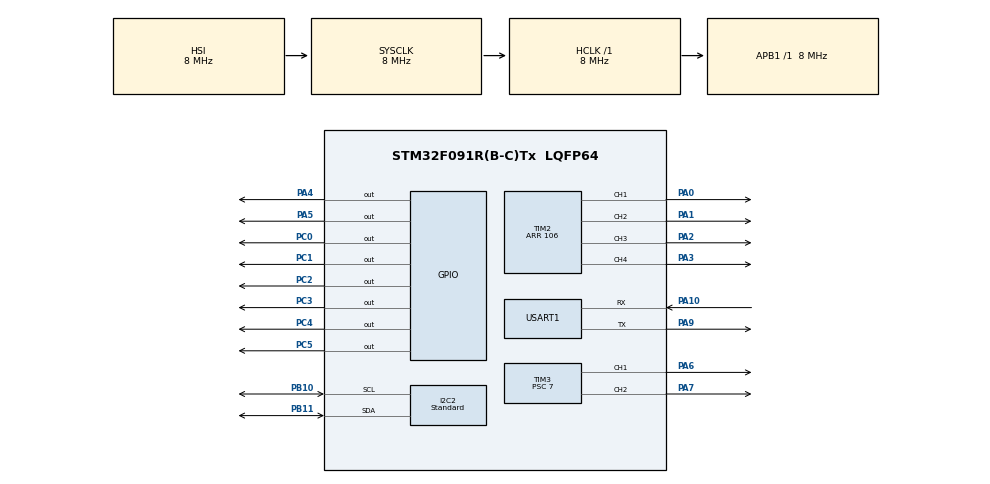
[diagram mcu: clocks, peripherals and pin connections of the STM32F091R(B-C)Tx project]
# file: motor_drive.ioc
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Dma.I2C2_RX.0.Direction=DMA_PERIPH_TO_MEMORY
Dma.I2C2_RX.0.Instance=DMA1_Channel5
Dma.I2C2_RX.0.MemDataAlignment=DMA_MDATAALIGN_BYTE
Dma.I2C2_RX.0.MemInc=DMA_MINC_ENABLE
Dma.I2C2_RX.0.Mode=DMA_NORMAL
Dma.I2C2_RX.0.PeriphDataAlignment=DMA_PDATAALIGN_BYTE
Dma.I2C2_RX.0.PeriphInc=DMA_PINC_DISABLE
Dma.I2C2_RX.0.Priority=DMA_PRIORITY_HIGH
Dma.I2C2_TX.1.Direction=DMA_MEMORY_TO_PERIPH
Dma.I2C2_TX.1.Instance=DMA1_Channel4
Dma.I2C2_TX.1.MemDataAlignment=DMA_MDATAALIGN_BYTE
Dma.I2C2_TX.1.MemInc=DMA_MINC_ENABLE
Dma.I2C2_TX.1.Mode=DMA_NORMAL
Dma.I2C2_TX.1.PeriphDataAlignment=DMA_PDATAALIGN_BYTE
Dma.I2C2_TX.1.PeriphInc=DMA_PINC_DISABLE
Dma.I2C2_TX.1.Priority=DMA_PRIORITY_HIGH
Dma.Request0=I2C2_RX
Dma.Request1=I2C2_TX
Dma.Request2=USART1_RX
Dma.Request3=USART1_TX
Dma.USART1_RX.2.Direction=DMA_PERIPH_TO_MEMORY
Dma.USART1_RX.2.Instance=DMA1_Channel1
Dma.USART1_RX.2.MemDataAlignment=DMA_MDATAALIGN_BYTE
Dma.USART1_RX.2.MemInc=DMA_MINC_ENABLE
Dma.USART1_RX.2.Mode=DMA_CIRCULAR
Dma.USART1_RX.2.PeriphDataAlignment=DMA_PDATAALIGN_BYTE
Dma.USART1_RX.2.PeriphInc=DMA_PINC_DISABLE
Dma.USART1_RX.2.Priority=DMA_PRIORITY_LOW
Dma.USART1_TX.3.Direction=DMA_MEMORY_TO_PERIPH
Dma.USART1_TX.3.Instance=DMA1_Channel2
Dma.USART1_TX.3.MemDataAlignment=DMA_MDATAALIGN_BYTE
Dma.USART1_TX.3.MemInc=DMA_MINC_ENABLE
Dma.USART1_TX.3.Mode=DMA_NORMAL
Dma.USART1_TX.3.PeriphDataAlignment=DMA_PDATAALIGN_BYTE
Dma.USART1_TX.3.PeriphInc=DMA_PINC_DISABLE
Dma.USART1_TX.3.Priority=DMA_PRIORITY_LOW
I2C2.I2C_Speed_Mode=I2C_Standard
I2C2.Speed=88
I2C2.Timing=0x00101D37
Mcu.Family=STM32F0
Mcu.Name=STM32F091R(B-C)Tx
Mcu.Package=LQFP64
NVIC.DMA1_Ch1_IRQn=true\:0\:0\:false\:false\:true\:false\:true\:true
NVIC.DMA1_Ch2_3_DMA2_Ch1_2_IRQn=true\:0\:0\:false\:false\:true\:false\:true\:true
NVIC.DMA1_Ch4_7_DMA2_Ch3_5_IRQn=true\:0\:0\:false\:false\:true\:false\:true\:true
NVIC.I2C2_IRQn=true\:0\:0\:false\:false\:true\:true\:true\:true
NVIC.TIM6_DAC_IRQn=true\:0\:0\:false\:false\:true\:true\:true\:true
NVIC.USART1_IRQn=true\:0\:0\:false\:false\:true\:true\:true\:true
PA0.Signal=S_TIM2_CH1_ETR
PA1.Signal=S_TIM2_CH2
PA10.Mode=Asynchronous
PA10.Signal=USART1_RX
PA2.Signal=S_TIM2_CH3
PA3.Signal=S_TIM2_CH4
PA4.Signal=GPIO_Output
PA5.Signal=GPIO_Output
PA6.Signal=S_TIM3_CH1
PA7.Signal=S_TIM3_CH2
PA9.Mode=Asynchronous
PA9.Signal=USART1_TX
PB10.Mode=I2C
PB10.Signal=I2C2_SCL
PB11.Mode=I2C
PB11.Signal=I2C2_SDA
PC0.Signal=GPIO_Output
PC1.Signal=GPIO_Output
PC2.Signal=GPIO_Output
PC3.Signal=GPIO_Output
PC4.Signal=GPIO_Output
PC5.Signal=GPIO_Output
PF0-OSC_IN.Mode=HSE-External-Oscillator
PF0-OSC_IN.Signal=RCC_OSC_IN
PF1-OSC_OUT.Mode=HSE-External-Oscillator
PF1-OSC_OUT.Signal=RCC_OSC_OUT
ProjectManager.HeapSize=0x200
ProjectManager.StackSize=0x400
ProjectManager.TargetToolchain=STM32CubeIDE
RCC.AHBFreq_Value=8000000
RCC.APB1Freq_Value=8000000
RCC.APB1TimFreq_Value=8000000
RCC.HCLKFreq_Value=8000000
RCC.SYSCLKFreq_VALUE=8000000
SH.S_TIM2_CH1_ETR.0=TIM2_CH1,PWM Generation1 CH1
SH.S_TIM2_CH2.0=TIM2_CH2,PWM Generation2 CH2
SH.S_TIM2_CH3.0=TIM2_CH3,PWM Generation3 CH3
SH.S_TIM2_CH4.0=TIM2_CH4,PWM Generation4 CH4
SH.S_TIM3_CH1.0=TIM3_CH1,PWM Generation1 CH1
SH.S_TIM3_CH2.0=TIM3_CH2,PWM Generation2 CH2
TIM2.Channel-PWM\ Generation1\ CH1=TIM_CHANNEL_1
TIM2.Channel-PWM\ Generation2\ CH2=TIM_CHANNEL_2
TIM2.Channel-PWM\ Generation3\ CH3=TIM_CHANNEL_3
TIM2.Channel-PWM\ Generation4\ CH4=TIM_CHANNEL_4
TIM2.Period=106
TIM2.Pulse-PWM\ Generation2\ CH2=0
TIM3.Channel-PWM\ Generation1\ CH1=TIM_CHANNEL_1
TIM3.Channel-PWM\ Generation2\ CH2=TIM_CHANNEL_2
TIM3.Period=19999
TIM3.Prescaler=7
TIM6.AutoReloadPreload=TIM_AUTORELOAD_PRELOAD_ENABLE
TIM6.Period=1947
TIM6.Prescaler=7
USART1.VirtualMode-Asynchronous=VM_ASYNC
VP_TIM2_VS_ClockSourceINT.Mode=Internal
VP_TIM3_VS_ClockSourceINT.Mode=Internal
VP_TIM6_VS_ClockSourceINT.Mode=Enable_Timer
board=custom

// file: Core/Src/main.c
/* USER CODE BEGIN Header */
/**
  ******************************************************************************
  * @file           : main.c
  * @brief          : Main program body
  ******************************************************************************
  * @attention
  *
  * Copyright (c) 2023 STMicroelectronics.
  * All rights reserved.
  *
  * This software is licensed under terms that can be found in the LICENSE file
  * in the root directory of this software component.
  * If no LICENSE file comes with this software, it is provided AS-IS.
  *
  ******************************************************************************
  */
/* USER CODE END Header */
#include "main.h"
#include "UART_Driver.h"
#include "i2c_proc.h"
#include "motor_proc.h"
#include "Jetson_Bridge.h"
#include "UART_Driver_Defines.h"
#include "servo_proc.h"

/* USER CODE BEGIN PD */
#define CW 1
#define CCW 0
/* USER CODE END PD */

I2C_HandleTypeDef hi2c2;
DMA_HandleTypeDef hdma_i2c2_rx;
DMA_HandleTypeDef hdma_i2c2_tx;
TIM_HandleTypeDef htim2;
TIM_HandleTypeDef htim3;
TIM_HandleTypeDef htim6;

UART_HandleTypeDef huart1;
DMA_HandleTypeDef hdma_usart1_rx;
DMA_HandleTypeDef hdma_usart1_tx;

void SystemClock_Config(void);
static void MX_GPIO_Init(void);
static void MX_DMA_Init(void);
static void MX_TIM2_Init(void);
static void MX_TIM3_Init(void);
static void MX_TIM6_Init(void);
static void MX_I2C2_Init(void);
static void MX_USART1_UART_Init(void);

int main(void)
{
  /* Reset of all peripherals, Initializes the Flash interface and the Systick. */
  HAL_Init();

  /* Configure the system clock */
  SystemClock_Config();

  /* Initialize all configured peripherals */
  MX_GPIO_Init();
  MX_DMA_Init();
  MX_TIM2_Init();
  MX_TIM3_Init();
  MX_TIM6_Init();
  MX_I2C2_Init();
  MX_USART1_UART_Init();

  HAL_TIM_PWM_Start(&htim2, TIM_CHANNEL_1);
  HAL_TIM_PWM_Start(&htim2, TIM_CHANNEL_2);
  HAL_TIM_PWM_Start(&htim2, TIM_CHANNEL_3);
  HAL_TIM_PWM_Start(&htim2, TIM_CHANNEL_4);
  HAL_TIM_PWM_Start(&htim3, TIM_CHANNEL_1);
  HAL_TIM_PWM_Start(&htim3, TIM_CHANNEL_2);

  MX_TIM6_Init();
  UART_Driver_RxInit();

  uint8_t gyro_on = 0b10000000;
  uint8_t accel_on = 0b10000000;
  (void) HAL_I2C_IsDeviceReady(&hi2c2, 212, 1, 100);
  (void) HAL_I2C_Mem_Write(&hi2c2, 212, 0x11, I2C_MEMADD_SIZE_8BIT, &gyro_on, 1, HAL_MAX_DELAY);
  (void) HAL_I2C_Mem_Write(&hi2c2, 212, 0x10, I2C_MEMADD_SIZE_8BIT, &accel_on, 1, HAL_MAX_DELAY);
  HAL_TIM_Base_Start_IT(&htim6);

  /* Infinite loop */
  while (1){
    if(!servo_proc_GetClose()) //open
    {
      servo1_control(120);
      servo2_control(20);
    }
    else //closed
    {
      servo2_control(120);
      for(int i=0;i<1000;i++)for(int j=0;j<150;j++)__NOP();
      servo1_control(160);
    }
  }
}

void SystemClock_Config(void)
{
  RCC_OscInitTypeDef RCC_OscInitStruct = {0};
  RCC_ClkInitTypeDef RCC_ClkInitStruct = {0};
  RCC_PeriphCLKInitTypeDef PeriphClkInit = {0};

  /** Initializes the RCC Oscillators according to the specified parameters
  * in the RCC_OscInitTypeDef structure.
  */
  RCC_OscInitStruct.OscillatorType = RCC_OSCILLATORTYPE_HSI;
  RCC_OscInitStruct.HSIState = RCC_HSI_ON;
  RCC_OscInitStruct.HSICalibrationValue = RCC_HSICALIBRATION_DEFAULT;
  RCC_OscInitStruct.PLL.PLLState = RCC_PLL_NONE;
  if (HAL_RCC_OscConfig(&RCC_OscInitStruct) != HAL_OK)
  {
    Error_Handler();
  }

  /** Initializes the CPU, AHB and APB buses clocks
  */
  RCC_ClkInitStruct.ClockType = RCC_CLOCKTYPE_HCLK|RCC_CLOCKTYPE_SYSCLK
                              |RCC_CLOCKTYPE_PCLK1;
  RCC_ClkInitStruct.SYSCLKSource = RCC_SYSCLKSOURCE_HSI;
  RCC_ClkInitStruct.AHBCLKDivider = RCC_SYSCLK_DIV1;
  RCC_ClkInitStruct.APB1CLKDivider = RCC_HCLK_DIV1;

  if (HAL_RCC_ClockConfig(&RCC_ClkInitStruct, FLASH_LATENCY_0) != HAL_OK)
  {
    Error_Handler();
  }
  PeriphClkInit.PeriphClockSelection = RCC_PERIPHCLK_USART1;
  PeriphClkInit.Usart1ClockSelection = RCC_USART1CLKSOURCE_PCLK1;
  if (HAL_RCCEx_PeriphCLKConfig(&PeriphClkInit) != HAL_OK)
  {
    Error_Handler();
  }
}

static void MX_I2C2_Init(void)
{
  hi2c2.Instance = I2C2;
  hi2c2.Init.Timing = 0x00101D37;
  hi2c2.Init.OwnAddress1 = 0;
  hi2c2.Init.AddressingMode = I2C_ADDRESSINGMODE_7BIT;
  hi2c2.Init.DualAddressMode = I2C_DUALADDRESS_DISABLE;
  hi2c2.Init.OwnAddress2 = 0;
  hi2c2.Init.OwnAddress2Masks = I2C_OA2_NOMASK;
  hi2c2.Init.GeneralCallMode = I2C_GENERALCALL_DISABLE;
  hi2c2.Init.NoStretchMode = I2C_NOSTRETCH_DISABLE;
  if (HAL_I2C_Init(&hi2c2) != HAL_OK)
  {
    Error_Handler();
  }

  /** Configure Analogue filter
  */
  if (HAL_I2CEx_ConfigAnalogFilter(&hi2c2, I2C_ANALOGFILTER_ENABLE) != HAL_OK)
  {
    Error_Handler();
  }

  /** Configure Digital filter
  */
  if (HAL_I2CEx_ConfigDigitalFilter(&hi2c2, 0) != HAL_OK)
  {
    Error_Handler();
  }
}

static void MX_TIM2_Init(void)
{
  TIM_ClockConfigTypeDef sClockSourceConfig = {0};
  TIM_MasterConfigTypeDef sMasterConfig = {0};
  TIM_OC_InitTypeDef sConfigOC = {0};

  htim2.Instance = TIM2;
  htim2.Init.Prescaler = 0;
  htim2.Init.CounterMode = TIM_COUNTERMODE_UP;
  htim2.Init.Period = 106;
  htim2.Init.ClockDivision = TIM_CLOCKDIVISION_DIV1;
  htim2.Init.AutoReloadPreload = TIM_AUTORELOAD_PRELOAD_DISABLE;
  if (HAL_TIM_Base_Init(&htim2) != HAL_OK)
  {
    Error_Handler();
  }
  sClockSourceConfig.ClockSource = TIM_CLOCKSOURCE_INTERNAL;
  if (HAL_TIM_ConfigClockSource(&htim2, &sClockSourceConfig) != HAL_OK)
  {
    Error_Handler();
  }
  if (HAL_TIM_PWM_Init(&htim2) != HAL_OK)
  {
    Error_Handler();
  }
  sMasterConfig.MasterOutputTrigger = TIM_TRGO_RESET;
  sMasterConfig.MasterSlaveMode = TIM_MASTERSLAVEMODE_DISABLE;
  if (HAL_TIMEx_MasterConfigSynchronization(&htim2, &sMasterConfig) != HAL_OK)
  {
    Error_Handler();
  }
  sConfigOC.OCMode = TIM_OCMODE_PWM1;
  sConfigOC.Pulse = 0;
  sConfigOC.OCPolarity = TIM_OCPOLARITY_HIGH;
  sConfigOC.OCFastMode = TIM_OCFAST_DISABLE;
  if (HAL_TIM_PWM_ConfigChannel(&htim2, &sConfigOC, TIM_CHANNEL_1) != HAL_OK)
  {
    Error_Handler();
  }
  if (HAL_TIM_PWM_ConfigChannel(&htim2, &sConfigOC, TIM_CHANNEL_2) != HAL_OK)
  {
    Error_Handler();
  }
  if (HAL_TIM_PWM_ConfigChannel(&htim2, &sConfigOC, TIM_CHANNEL_3) != HAL_OK)
  {
    Error_Handler();
  }
  if (HAL_TIM_PWM_ConfigChannel(&htim2, &sConfigOC, TIM_CHANNEL_4) != HAL_OK)
  {
    Error_Handler();
  }

  HAL_TIM_MspPostInit(&htim2);

}

static void MX_TIM3_Init(void)
{
  TIM_ClockConfigTypeDef sClockSourceConfig = {0};
  TIM_MasterConfigTypeDef sMasterConfig = {0};
  TIM_OC_InitTypeDef sConfigOC = {0};

  htim3.Instance = TIM3;
  htim3.Init.Prescaler = 7;
  htim3.Init.CounterMode = TIM_COUNTERMODE_UP;
  htim3.Init.Period = 19999;
  htim3.Init.ClockDivision = TIM_CLOCKDIVISION_DIV1;
  htim3.Init.AutoReloadPreload = TIM_AUTORELOAD_PRELOAD_DISABLE;
  if (HAL_TIM_Base_Init(&htim3) != HAL_OK)
  {
    Error_Handler();
  }
  sClockSourceConfig.ClockSource = TIM_CLOCKSOURCE_INTERNAL;
  if (HAL_TIM_ConfigClockSource(&htim3, &sClockSourceConfig) != HAL_OK)
  {
    Error_Handler();
  }
  if (HAL_TIM_PWM_Init(&htim3) != HAL_OK)
  {
    Error_Handler();
  }
  sMasterConfig.MasterOutputTrigger = TIM_TRGO_RESET;
  sMasterConfig.MasterSlaveMode = TIM_MASTERSLAVEMODE_DISABLE;
  if (HAL_TIMEx_MasterConfigSynchronization(&htim3, &sMasterConfig) != HAL_OK)
  {
    Error_Handler();
  }
  sConfigOC.OCMode = TIM_OCMODE_PWM1;
  sConfigOC.Pulse = 0;
  sConfigOC.OCPolarity = TIM_OCPOLARITY_HIGH;
  sConfigOC.OCFastMode = TIM_OCFAST_DISABLE;
  if (HAL_TIM_PWM_ConfigChannel(&htim3, &sConfigOC, TIM_CHANNEL_1) != HAL_OK)
  {
    Error_Handler();
  }
  if (HAL_TIM_PWM_ConfigChannel(&htim3, &sConfigOC, TIM_CHANNEL_2) != HAL_OK)
  {
    Error_Handler();
  }
  HAL_TIM_MspPostInit(&htim3);

}

static void MX_TIM6_Init(void)
{

  TIM_MasterConfigTypeDef sMasterConfig = {0};

  htim6.Instance = TIM6;
  htim6.Init.Prescaler = 9;
  htim6.Init.CounterMode = TIM_COUNTERMODE_UP;
  htim6.Init.Period = 13332;
  htim6.Init.AutoReloadPreload = TIM_AUTORELOAD_PRELOAD_ENABLE;
  if (HAL_TIM_Base_Init(&htim6) != HAL_OK)
  {
    Error_Handler();
  }
  sMasterConfig.MasterOutputTrigger = TIM_TRGO_RESET;
  sMasterConfig.MasterSlaveMode = TIM_MASTERSLAVEMODE_DISABLE;
  if (HAL_TIMEx_MasterConfigSynchronization(&htim6, &sMasterConfig) != HAL_OK)
  {
    Error_Handler();
  }
}

static void MX_USART1_UART_Init(void)
{
  huart1.Instance = USART1;
  huart1.Init.BaudRate = 230400;
  huart1.Init.WordLength = UART_WORDLENGTH_8B;
  huart1.Init.StopBits = UART_STOPBITS_1;
  huart1.Init.Parity = UART_PARITY_NONE;
  huart1.Init.Mode = UART_MODE_TX_RX;
  huart1.Init.HwFlowCtl = UART_HWCONTROL_NONE;
  huart1.Init.OverSampling = UART_OVERSAMPLING_16;
  huart1.Init.OneBitSampling = UART_ONE_BIT_SAMPLE_DISABLE;
  huart1.AdvancedInit.AdvFeatureInit = UART_ADVFEATURE_NO_INIT;
  if (HAL_UART_Init(&huart1) != HAL_OK)
  {
    Error_Handler();
  }

}

static void MX_DMA_Init(void)
{

  /* DMA controller clock enable */
  __HAL_RCC_DMA1_CLK_ENABLE();

  /* DMA interrupt init */
  /* DMA1_Ch1_IRQn interrupt configuration */
  HAL_NVIC_SetPriority(DMA1_Ch1_IRQn, 0, 0);
  HAL_NVIC_EnableIRQ(DMA1_Ch1_IRQn);
  /* DMA1_Ch2_3_DMA2_Ch1_2_IRQn interrupt configuration */
  HAL_NVIC_SetPriority(DMA1_Ch2_3_DMA2_Ch1_2_IRQn, 0, 0);
  HAL_NVIC_EnableIRQ(DMA1_Ch2_3_DMA2_Ch1_2_IRQn);

}

static void MX_GPIO_Init(void)
{
  GPIO_InitTypeDef GPIO_InitStruct = {0};

  /* GPIO Ports Clock Enable */
  __HAL_RCC_GPIOF_CLK_ENABLE();
  __HAL_RCC_GPIOC_CLK_ENABLE();
  __HAL_RCC_GPIOA_CLK_ENABLE();
  __HAL_RCC_GPIOB_CLK_ENABLE();

  /*Configure GPIO pin Output Level */
  HAL_GPIO_WritePin(GPIOC, GPIO_PIN_0|GPIO_PIN_1|GPIO_PIN_2|GPIO_PIN_3
                          |GPIO_PIN_4|GPIO_PIN_5, GPIO_PIN_RESET);

  /*Configure GPIO pin Output Level */
  HAL_GPIO_WritePin(GPIOA, GPIO_PIN_4|GPIO_PIN_5, GPIO_PIN_RESET);

  /*Configure GPIO pins : PC0 PC1 PC2 PC3
                           PC4 PC5 */
  GPIO_InitStruct.Pin = GPIO_PIN_0|GPIO_PIN_1|GPIO_PIN_2|GPIO_PIN_3
                          |GPIO_PIN_4|GPIO_PIN_5;
  GPIO_InitStruct.Mode = GPIO_MODE_OUTPUT_PP;
  GPIO_InitStruct.Pull = GPIO_NOPULL;
  GPIO_InitStruct.Speed = GPIO_SPEED_FREQ_LOW;
  HAL_GPIO_Init(GPIOC, &GPIO_InitStruct);

  /*Configure GPIO pins : PA4 PA5 */
  GPIO_InitStruct.Pin = GPIO_PIN_4|GPIO_PIN_5;
  GPIO_InitStruct.Mode = GPIO_MODE_OUTPUT_PP;
  GPIO_InitStruct.Pull = GPIO_NOPULL;
  GPIO_InitStruct.Speed = GPIO_SPEED_FREQ_LOW;
  HAL_GPIO_Init(GPIOA, &GPIO_InitStruct);
}

void HAL_TIM_PeriodElapsedCallback(TIM_HandleTypeDef* htim)
{
  i2c_proc_updateAccelData(hi2c2);
  i2c_proc_updateGyroData(hi2c2);
  Jetson_Bridge_TxGyro();
  Jetson_Bridge_TxAccel();

}

void Error_Handler(void)
{
  /* User can add his own implementation to report the HAL error return state */
  __disable_irq();
  while (1)
  {
  }
}
